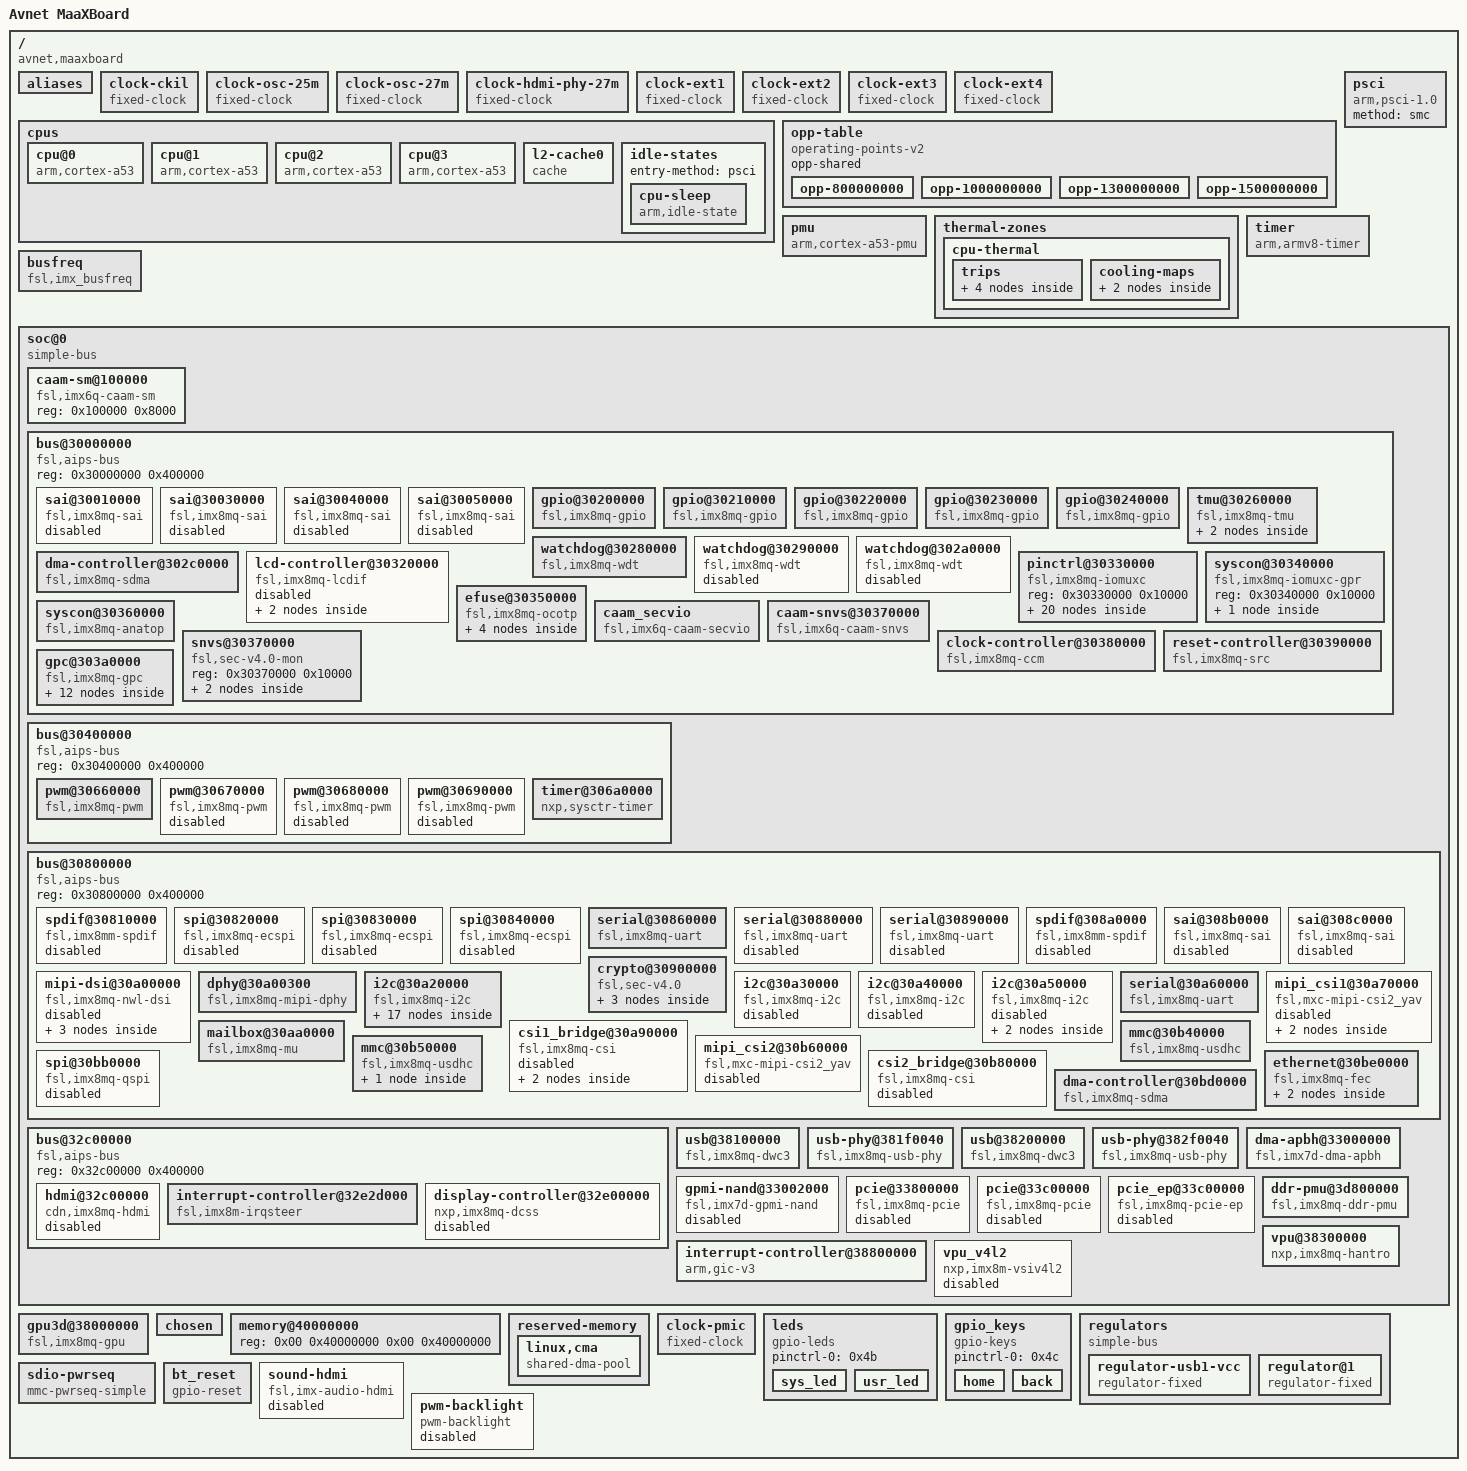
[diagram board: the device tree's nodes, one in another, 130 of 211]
/dts-v1/;

/ {
	interrupt-parent = <0x01>;
	#address-cells = <0x02>;
	#size-cells = <0x02>;
	model = "Avnet MaaXBoard";
	compatible = "avnet,maaxboard", "fsl,imx8mq";

	aliases {
		csi0 = "/soc@0/bus@30800000/mipi_csi1@30a70000";
		csi1 = "/soc@0/bus@30800000/mipi_csi2@30b60000";
		ethernet0 = "/soc@0/bus@30800000/ethernet@30be0000";
		gpio0 = "/soc@0/bus@30000000/gpio@30200000";
		gpio1 = "/soc@0/bus@30000000/gpio@30210000";
		gpio2 = "/soc@0/bus@30000000/gpio@30220000";
		gpio3 = "/soc@0/bus@30000000/gpio@30230000";
		gpio4 = "/soc@0/bus@30000000/gpio@30240000";
		i2c0 = "/soc@0/bus@30800000/i2c@30a20000";
		i2c1 = "/soc@0/bus@30800000/i2c@30a30000";
		i2c2 = "/soc@0/bus@30800000/i2c@30a40000";
		i2c3 = "/soc@0/bus@30800000/i2c@30a50000";
		mmc0 = "/soc@0/bus@30800000/mmc@30b40000";
		mmc1 = "/soc@0/bus@30800000/mmc@30b50000";
		serial0 = "/soc@0/bus@30800000/serial@30860000";
		serial1 = "/soc@0/bus@30800000/serial@30890000";
		serial2 = "/soc@0/bus@30800000/serial@30880000";
		serial3 = "/soc@0/bus@30800000/serial@30a60000";
		spi0 = "/soc@0/bus@30800000/spi@30820000";
		spi1 = "/soc@0/bus@30800000/spi@30830000";
		spi2 = "/soc@0/bus@30800000/spi@30840000";
	};

	clock-ckil {
		compatible = "fixed-clock";
		#clock-cells = <0x00>;
		clock-frequency = <0x8000>;
		clock-output-names = "ckil";
		phandle = <0x17>;
	};

	clock-osc-25m {
		compatible = "fixed-clock";
		#clock-cells = <0x00>;
		clock-frequency = <0x17d7840>;
		clock-output-names = "osc_25m";
		phandle = <0x18>;
	};

	clock-osc-27m {
		compatible = "fixed-clock";
		#clock-cells = <0x00>;
		clock-frequency = <0x19bfcc0>;
		clock-output-names = "osc_27m";
		phandle = <0x19>;
	};

	clock-hdmi-phy-27m {
		compatible = "fixed-clock";
		#clock-cells = <0x00>;
		clock-frequency = <0x19bfcc0>;
		clock-output-names = "hdmi_phy_27m";
		phandle = <0x42>;
	};

	clock-ext1 {
		compatible = "fixed-clock";
		#clock-cells = <0x00>;
		clock-frequency = <0x7ed6b40>;
		clock-output-names = "clk_ext1";
		phandle = <0x1a>;
	};

	clock-ext2 {
		compatible = "fixed-clock";
		#clock-cells = <0x00>;
		clock-frequency = <0x7ed6b40>;
		clock-output-names = "clk_ext2";
		phandle = <0x1b>;
	};

	clock-ext3 {
		compatible = "fixed-clock";
		#clock-cells = <0x00>;
		clock-frequency = <0x7ed6b40>;
		clock-output-names = "clk_ext3";
		phandle = <0x1c>;
	};

	clock-ext4 {
		compatible = "fixed-clock";
		#clock-cells = <0x00>;
		clock-frequency = <0x7ed6b40>;
		clock-output-names = "clk_ext4";
		phandle = <0x1d>;
	};

	cpus {
		#address-cells = <0x01>;
		#size-cells = <0x00>;

		cpu@0 {
			device_type = "cpu";
			compatible = "arm,cortex-a53";
			reg = <0x00>;
			clock-latency = <0xee6c>;
			clocks = <0x02 0x102>;
			enable-method = "psci";
			i-cache-size = <0x8000>;
			i-cache-line-size = <0x40>;
			i-cache-sets = <0x100>;
			d-cache-size = <0x8000>;
			d-cache-line-size = <0x40>;
			d-cache-sets = <0x80>;
			next-level-cache = <0x03>;
			operating-points-v2 = <0x04>;
			#cooling-cells = <0x02>;
			nvmem-cells = <0x05>;
			nvmem-cell-names = "speed_grade";
			cpu-idle-states = <0x06>;
			cpu-supply = <0x07>;
			phandle = <0x0c>;
		};

		cpu@1 {
			device_type = "cpu";
			compatible = "arm,cortex-a53";
			reg = <0x01>;
			clock-latency = <0xee6c>;
			clocks = <0x02 0x102>;
			enable-method = "psci";
			i-cache-size = <0x8000>;
			i-cache-line-size = <0x40>;
			i-cache-sets = <0x100>;
			d-cache-size = <0x8000>;
			d-cache-line-size = <0x40>;
			d-cache-sets = <0x80>;
			next-level-cache = <0x03>;
			operating-points-v2 = <0x04>;
			#cooling-cells = <0x02>;
			cpu-idle-states = <0x06>;
			cpu-supply = <0x07>;
			phandle = <0x0d>;
		};

		cpu@2 {
			device_type = "cpu";
			compatible = "arm,cortex-a53";
			reg = <0x02>;
			clock-latency = <0xee6c>;
			clocks = <0x02 0x102>;
			enable-method = "psci";
			i-cache-size = <0x8000>;
			i-cache-line-size = <0x40>;
			i-cache-sets = <0x100>;
			d-cache-size = <0x8000>;
			d-cache-line-size = <0x40>;
			d-cache-sets = <0x80>;
			next-level-cache = <0x03>;
			operating-points-v2 = <0x04>;
			#cooling-cells = <0x02>;
			cpu-idle-states = <0x06>;
			cpu-supply = <0x07>;
			phandle = <0x0e>;
		};

		cpu@3 {
			device_type = "cpu";
			compatible = "arm,cortex-a53";
			reg = <0x03>;
			clock-latency = <0xee6c>;
			clocks = <0x02 0x102>;
			enable-method = "psci";
			i-cache-size = <0x8000>;
			i-cache-line-size = <0x40>;
			i-cache-sets = <0x100>;
			d-cache-size = <0x8000>;
			d-cache-line-size = <0x40>;
			d-cache-sets = <0x80>;
			next-level-cache = <0x03>;
			operating-points-v2 = <0x04>;
			#cooling-cells = <0x02>;
			cpu-idle-states = <0x06>;
			cpu-supply = <0x07>;
			phandle = <0x0f>;
		};

		l2-cache0 {
			compatible = "cache";
			cache-level = <0x02>;
			cache-size = <0x100000>;
			cache-line-size = <0x40>;
			cache-sets = <0x400>;
			phandle = <0x03>;
		};

		idle-states {
			entry-method = "psci";

			cpu-sleep {
				compatible = "arm,idle-state";
				arm,psci-suspend-param = <0x10033>;
				local-timer-stop;
				entry-latency-us = <0x3e8>;
				exit-latency-us = <0x2bc>;
				min-residency-us = <0xa8c>;
				wakeup-latency-us = <0x5dc>;
				phandle = <0x06>;
			};
		};
	};

	opp-table {
		compatible = "operating-points-v2";
		opp-shared;
		phandle = <0x04>;

		opp-800000000 {
			opp-hz = <0x00 0x2faf0800>;
			opp-microvolt = <0xdbba0>;
			opp-supported-hw = <0x0f 0x04>;
			clock-latency-ns = <0x249f0>;
			opp-suspend;
		};

		opp-1000000000 {
			opp-hz = <0x00 0x3b9aca00>;
			opp-microvolt = <0xdbba0>;
			opp-supported-hw = <0x0e 0x03>;
			clock-latency-ns = <0x249f0>;
			opp-suspend;
		};

		opp-1300000000 {
			opp-hz = <0x00 0x4d7c6d00>;
			opp-microvolt = <0xf4240>;
			opp-supported-hw = <0x0c 0x04>;
			clock-latency-ns = <0x249f0>;
			opp-suspend;
		};

		opp-1500000000 {
			opp-hz = <0x00 0x59682f00>;
			opp-microvolt = <0xf4240>;
			opp-supported-hw = <0x08 0x03>;
			clock-latency-ns = <0x249f0>;
			opp-suspend;
		};
	};

	pmu {
		compatible = "arm,cortex-a53-pmu";
		interrupts = <0x01 0x07 0x04>;
		interrupt-parent = <0x08>;
	};

	psci {
		compatible = "arm,psci-1.0";
		method = "smc";
	};

	thermal-zones {

		cpu-thermal {
			polling-delay-passive = <0xfa>;
			polling-delay = <0x7d0>;
			thermal-sensors = <0x09 0x00>;
			phandle = <0x53>;

			trips {

				cpu-alert {
					temperature = <0x13880>;
					hysteresis = <0x7d0>;
					type = "passive";
					phandle = <0x54>;
				};

				cpu-crit {
					temperature = <0x17318>;
					hysteresis = <0x7d0>;
					type = "critical";
				};

				trip0 {
					temperature = <0x13880>;
					hysteresis = <0x7d0>;
					type = "passive";
					phandle = <0x0a>;
				};

				trip1 {
					temperature = <0x14c08>;
					hysteresis = <0x7d0>;
					type = "passive";
					phandle = <0x10>;
				};
			};

			cooling-maps {

				map0 {
					trip = <0x0a>;
					cooling-device = <0x0b 0x00 0x01 0x0c 0xffffffff 0xffffffff 0x0d 0xffffffff 0xffffffff 0x0e 0xffffffff 0xffffffff 0x0f 0xffffffff 0xffffffff>;
				};

				map1 {
					trip = <0x10>;
					cooling-device = <0x0b 0x00 0x02>;
				};
			};
		};
	};

	timer {
		compatible = "arm,armv8-timer";
		interrupts = <0x01 0x0d 0x08 0x01 0x0e 0x08 0x01 0x0b 0x08 0x01 0x0a 0x08>;
		interrupt-parent = <0x08>;
		arm,no-tick-in-suspend;
	};

	busfreq {
		compatible = "fsl,imx_busfreq";
		clocks = <0x02 0xea 0x02 0x76 0x02 0x77 0x02 0x77 0x02 0xfc 0x02 0xfb 0x02 0x46 0x02 0x4d 0x02 0x48 0x02 0x4e 0x02 0x71 0x02 0x67 0x02 0x74 0x02 0x02 0x02 0x55 0x02 0x49>;
		clock-names = "dram_pll", "dram_alt_src", "dram_apb_src", "dram_apb_pre_div", "dram_core", "dram_alt_root", "sys1_pll_40m", "sys1_pll_400m", "sys1_pll_100m", "sys1_pll_800m", "noc_div", "main_axi_src", "ahb_div", "osc_25m", "sys2_pll_333m", "sys1_pll_133m";
		interrupts = <0x00 0x66 0x04 0x00 0x6d 0x04 0x00 0x6e 0x04 0x00 0x6f 0x04>;
		interrupt-name = "irq_busfreq_0", "irq_busfreq_1", "irq_busfreq_2", "irq_busfreq_3";
	};

	soc@0 {
		compatible = "simple-bus";
		#address-cells = <0x01>;
		#size-cells = <0x01>;
		ranges = <0x00 0x00 0x00 0x3e000000>;
		dma-ranges = <0x40000000 0x00 0x40000000 0xc0000000>;
		nvmem-cells = <0x11>;
		nvmem-cell-names = "soc_unique_id";
		phandle = <0x55>;

		caam-sm@100000 {
			compatible = "fsl,imx6q-caam-sm";
			reg = <0x100000 0x8000>;
			phandle = <0x56>;
		};

		bus@30000000 {
			compatible = "fsl,aips-bus", "simple-bus";
			reg = <0x30000000 0x400000>;
			#address-cells = <0x01>;
			#size-cells = <0x01>;
			ranges = <0x30000000 0x30000000 0x400000>;
			phandle = <0x57>;

			sai@30010000 {
				#sound-dai-cells = <0x00>;
				compatible = "fsl,imx8mq-sai", "fsl,imx6sx-sai";
				reg = <0x30010000 0x10000>;
				interrupts = <0x00 0x5f 0x04>;
				clocks = <0x02 0xee 0x02 0x00 0x02 0xc4 0x02 0x00 0x02 0x00>;
				clock-names = "bus", "mclk0", "mclk1", "mclk2", "mclk3";
				dmas = <0x12 0x08 0x01 0x00 0x12 0x09 0x01 0x00>;
				dma-names = "rx", "tx";
				fsl,dataline = <0x00 0xff 0xff>;
				status = "disabled";
				phandle = <0x58>;
			};

			sai@30030000 {
				#sound-dai-cells = <0x00>;
				compatible = "fsl,imx8mq-sai", "fsl,imx6sx-sai";
				reg = <0x30030000 0x10000>;
				interrupts = <0x00 0x5a 0x04>;
				clocks = <0x02 0xf3 0x02 0x00 0x02 0xc9 0x02 0x00 0x02 0x00>;
				clock-names = "bus", "mclk0", "mclk1", "mclk2", "mclk3";
				dmas = <0x12 0x04 0x18 0x00 0x12 0x05 0x18 0x00>;
				dma-names = "rx", "tx";
				fsl,shared-interrupt;
				status = "disabled";
				phandle = <0x59>;
			};

			sai@30040000 {
				#sound-dai-cells = <0x00>;
				compatible = "fsl,imx8mq-sai", "fsl,imx6sx-sai";
				reg = <0x30040000 0x10000>;
				interrupts = <0x00 0x5a 0x04>;
				clocks = <0x02 0xf2 0x02 0x00 0x02 0xc8 0x02 0x00 0x02 0x00>;
				clock-names = "bus", "mclk0", "mclk1", "mclk2", "mclk3";
				dmas = <0x12 0x02 0x18 0x00 0x12 0x03 0x18 0x00>;
				dma-names = "rx", "tx";
				fsl,shared-interrupt;
				fsl,dataline = <0x00 0x0f 0x0f>;
				status = "disabled";
				phandle = <0x5a>;
			};

			sai@30050000 {
				#sound-dai-cells = <0x00>;
				compatible = "fsl,imx8mq-sai", "fsl,imx6sx-sai";
				reg = <0x30050000 0x10000>;
				interrupts = <0x00 0x64 0x04>;
				clocks = <0x02 0xf1 0x02 0x00 0x02 0xc7 0x02 0x00 0x02 0x00 0x02 0x1b 0x02 0x20>;
				clock-names = "bus", "mclk0", "mclk1", "mclk2", "mclk3", "pll8k", "pll11k";
				dmas = <0x12 0x00 0x18 0x00 0x12 0x01 0x18 0x00>;
				dma-names = "rx", "tx";
				fsl,dataline = <0x00 0x00 0x0f>;
				status = "disabled";
				assigned-clocks = <0x02 0x84>;
				assigned-clock-parents = <0x02 0x1b>;
				assigned-clock-rates = <0x1770000>;
				phandle = <0x51>;
			};

			gpio@30200000 {
				compatible = "fsl,imx8mq-gpio", "fsl,imx35-gpio";
				reg = <0x30200000 0x10000>;
				interrupts = <0x00 0x40 0x04 0x00 0x41 0x04>;
				clocks = <0x02 0x103>;
				gpio-controller;
				#gpio-cells = <0x02>;
				interrupt-controller;
				#interrupt-cells = <0x02>;
				gpio-ranges = <0x13 0x00 0x0a 0x1e>;
				phandle = <0x2c>;
			};

			gpio@30210000 {
				compatible = "fsl,imx8mq-gpio", "fsl,imx35-gpio";
				reg = <0x30210000 0x10000>;
				interrupts = <0x00 0x42 0x04 0x00 0x43 0x04>;
				clocks = <0x02 0x104>;
				gpio-controller;
				#gpio-cells = <0x02>;
				interrupt-controller;
				#interrupt-cells = <0x02>;
				gpio-ranges = <0x13 0x00 0x28 0x15>;
				phandle = <0x3c>;
			};

			gpio@30220000 {
				compatible = "fsl,imx8mq-gpio", "fsl,imx35-gpio";
				reg = <0x30220000 0x10000>;
				interrupts = <0x00 0x44 0x04 0x00 0x45 0x04>;
				clocks = <0x02 0x105>;
				gpio-controller;
				#gpio-cells = <0x02>;
				interrupt-controller;
				#interrupt-cells = <0x02>;
				gpio-ranges = <0x13 0x00 0x3d 0x1a>;
				phandle = <0x2f>;
			};

			gpio@30230000 {
				compatible = "fsl,imx8mq-gpio", "fsl,imx35-gpio";
				reg = <0x30230000 0x10000>;
				interrupts = <0x00 0x46 0x04 0x00 0x47 0x04>;
				clocks = <0x02 0x106>;
				gpio-controller;
				#gpio-cells = <0x02>;
				interrupt-controller;
				#interrupt-cells = <0x02>;
				gpio-ranges = <0x13 0x00 0x57 0x20>;
				phandle = <0x5b>;
			};

			gpio@30240000 {
				compatible = "fsl,imx8mq-gpio", "fsl,imx35-gpio";
				reg = <0x30240000 0x10000>;
				interrupts = <0x00 0x48 0x04 0x00 0x49 0x04>;
				clocks = <0x02 0x107>;
				gpio-controller;
				#gpio-cells = <0x02>;
				interrupt-controller;
				#interrupt-cells = <0x02>;
				gpio-ranges = <0x13 0x00 0x77 0x1e>;
				phandle = <0x50>;
			};

			tmu@30260000 {
				compatible = "fsl,imx8mq-tmu";
				reg = <0x30260000 0x10000>;
				interrupts = <0x00 0x31 0x04>;
				clocks = <0x02 0xf6>;
				little-endian;
				fsl,tmu-range = <0xb0000 0xa0026 0x80048 0x70061>;
				fsl,tmu-calibration = <0x00 0x23 0x01 0x29 0x02 0x2f 0x03 0x35 0x04 0x3d 0x05 0x43 0x06 0x4b 0x07 0x51 0x08 0x57 0x09 0x5f 0x0a 0x67 0x0b 0x6f 0x10000 0x1b 0x10001 0x23 0x10002 0x2b 0x10003 0x33 0x10004 0x3b 0x10005 0x43 0x10006 0x4b 0x10007 0x55 0x10008 0x5d 0x10009 0x67 0x1000a 0x70 0x20000 0x17 0x20001 0x23 0x20002 0x2d 0x20003 0x37 0x20004 0x41 0x20005 0x4b 0x20006 0x57 0x20007 0x63 0x20008 0x6f 0x30000 0x15 0x30001 0x21 0x30002 0x2d 0x30003 0x39 0x30004 0x45 0x30005 0x53 0x30006 0x5f 0x30007 0x71>;
				#thermal-sensor-cells = <0x01>;
				phandle = <0x09>;

				throttle-cfgs {

					devfreq {
						throttle,max_state = <0x02>;
						#cooling-cells = <0x02>;
						phandle = <0x0b>;
					};
				};
			};

			watchdog@30280000 {
				compatible = "fsl,imx8mq-wdt", "fsl,imx21-wdt";
				reg = <0x30280000 0x10000>;
				interrupts = <0x00 0x4e 0x04>;
				clocks = <0x02 0xd4>;
				status = "okay";
				pinctrl-names = "default";
				pinctrl-0 = <0x14>;
				fsl,ext-reset-output;
				phandle = <0x5c>;
			};

			watchdog@30290000 {
				compatible = "fsl,imx8mq-wdt", "fsl,imx21-wdt";
				reg = <0x30290000 0x10000>;
				interrupts = <0x00 0x4f 0x04>;
				clocks = <0x02 0xd5>;
				status = "disabled";
				phandle = <0x5d>;
			};

			watchdog@302a0000 {
				compatible = "fsl,imx8mq-wdt", "fsl,imx21-wdt";
				reg = <0x302a0000 0x10000>;
				interrupts = <0x00 0x0a 0x04>;
				clocks = <0x02 0xd6>;
				status = "disabled";
				phandle = <0x5e>;
			};

			dma-controller@302c0000 {
				compatible = "fsl,imx8mq-sdma", "fsl,imx7d-sdma";
				reg = <0x302c0000 0x10000>;
				interrupts = <0x00 0x67 0x04>;
				clocks = <0x02 0xe4 0x02 0xe4>;
				clock-names = "ipg", "ahb";
				#dma-cells = <0x03>;
				fsl,sdma-ram-script-name = "imx/sdma/sdma-imx7d.bin";
				phandle = <0x12>;
			};

			lcd-controller@30320000 {
				compatible = "fsl,imx8mq-lcdif", "fsl,imx28-lcdif";
				reg = <0x30320000 0x10000>;
				interrupts = <0x00 0x05 0x04>;
				clocks = <0x02 0x80>;
				clock-names = "pix";
				assigned-clocks = <0x02 0x21 0x02 0x24 0x02 0x80 0x02 0x23>;
				assigned-clock-parents = <0x02 0x02 0x02 0x23 0x02 0x25>;
				assigned-clock-rates = <0x00 0x00 0x00 0x2367b880>;
				status = "disabled";
				phandle = <0x5f>;

				port {

					endpoint {
						remote-endpoint = <0x15>;
						phandle = <0x28>;
					};
				};
			};

			pinctrl@30330000 {
				compatible = "fsl,imx8mq-iomuxc";
				reg = <0x30330000 0x10000>;
				pinctrl-names = "default";
				phandle = <0x13>;

				ir-recv {
					fsl,pins = <0x58 0x2c0 0x00 0x00 0x00 0x4f>;
					phandle = <0x60>;
				};

				pmicirq {
					fsl,pins = <0x44 0x2ac 0x00 0x00 0x00 0x19>;
					phandle = <0x2a>;
				};

				fec1grp {
					fsl,pins = <0x68 0x2d0 0x00 0x00 0x00 0x03 0x6c 0x2d4 0x4c0 0x00 0x01 0x23 0x70 0x2d8 0x00 0x00 0x00 0x1f 0x74 0x2dc 0x00 0x00 0x00 0x1f 0x78 0x2e0 0x00 0x00 0x00 0x1f 0x7c 0x2e4 0x00 0x00 0x00 0x1f 0x9c 0x304 0x00 0x00 0x00 0x91 0x98 0x300 0x00 0x00 0x00 0x91 0x94 0x2fc 0x00 0x00 0x00 0x91 0x90 0x2f8 0x00 0x00 0x00 0x91 0x84 0x2ec 0x00 0x00 0x00 0x1f 0x8c 0x2f4 0x00 0x00 0x00 0x91 0x88 0x2f0 0x00 0x00 0x00 0x91 0x80 0x2e8 0x00 0x00 0x00 0x1f 0x4c 0x2b4 0x00 0x00 0x00 0x19>;
					phandle = <0x3f>;
				};

				i2c1grp {
					fsl,pins = <0x214 0x47c 0x00 0x00 0x00 0x4000007f 0x218 0x480 0x00 0x00 0x00 0x4000007f>;
					phandle = <0x29>;
				};

				uart1grp {
					fsl,pins = <0x234 0x49c 0x4f4 0x00 0x00 0x49 0x238 0x4a0 0x00 0x00 0x00 0x49>;
					phandle = <0x23>;
				};

				usdhc1grp {
					fsl,pins = <0xa0 0x308 0x00 0x00 0x00 0x83 0xa4 0x30c 0x00 0x00 0x00 0xc3 0xa8 0x310 0x00 0x00 0x00 0xc3 0xac 0x314 0x00 0x00 0x00 0xc3 0xb0 0x318 0x00 0x00 0x00 0xc3 0xb4 0x31c 0x00 0x00 0x00 0xc3 0xb8 0x320 0x00 0x00 0x00 0xc3 0xbc 0x324 0x00 0x00 0x00 0xc3 0xc0 0x328 0x00 0x00 0x00 0xc3 0xc4 0x32c 0x00 0x00 0x00 0xc3 0xcc 0x334 0x00 0x00 0x00 0x83 0xc8 0x330 0x00 0x00 0x00 0xc1>;
					phandle = <0x36>;
				};

				usdhc1-100grp {
					fsl,pins = <0xa0 0x308 0x00 0x00 0x00 0x8d 0xa4 0x30c 0x00 0x00 0x00 0xcd 0xa8 0x310 0x00 0x00 0x00 0xcd 0xac 0x314 0x00 0x00 0x00 0xcd 0xb0 0x318 0x00 0x00 0x00 0xcd 0xb4 0x31c 0x00 0x00 0x00 0xcd 0xb8 0x320 0x00 0x00 0x00 0xcd 0xbc 0x324 0x00 0x00 0x00 0xcd 0xc0 0x328 0x00 0x00 0x00 0xcd 0xc4 0x32c 0x00 0x00 0x00 0xcd 0xcc 0x334 0x00 0x00 0x00 0x8d 0xc8 0x330 0x00 0x00 0x00 0xc1>;
					phandle = <0x37>;
				};

				usdhc1-200grp {
					fsl,pins = <0xa0 0x308 0x00 0x00 0x00 0x9f 0xa4 0x30c 0x00 0x00 0x00 0xdf 0xa8 0x310 0x00 0x00 0x00 0xdf 0xac 0x314 0x00 0x00 0x00 0xdf 0xb0 0x318 0x00 0x00 0x00 0xdf 0xb4 0x31c 0x00 0x00 0x00 0xdf 0xb8 0x320 0x00 0x00 0x00 0xdf 0xbc 0x324 0x00 0x00 0x00 0xdf 0xc0 0x328 0x00 0x00 0x00 0xdf 0xc4 0x32c 0x00 0x00 0x00 0xdf 0xcc 0x334 0x00 0x00 0x00 0x9f 0xc8 0x330 0x00 0x00 0x00 0xc1>;
					phandle = <0x38>;
				};

				gpio_ledsgrp {
					fsl,pins = <0x3c 0x2a4 0x00 0x00 0x00 0x19 0x48 0x2b0 0x00 0x00 0x00 0x19>;
					phandle = <0x4b>;
				};

				gpio_keysgrp {
					fsl,pins = <0x110 0x378 0x00 0x05 0x00 0x56 0x10c 0x374 0x00 0x05 0x00 0x56>;
					phandle = <0x4c>;
				};

				usb1_pwr_en {
					fsl,pins = <0x58 0x2c0 0x00 0x00 0x00 0x16>;
					phandle = <0x4d>;
				};

				usdhc2grp {
					fsl,pins = <0xd4 0x33c 0x00 0x00 0x00 0x83 0xd8 0x340 0x00 0x00 0x00 0xc3 0xdc 0x344 0x00 0x00 0x00 0xc3 0xe0 0x348 0x00 0x00 0x00 0xc3 0xe4 0x34c 0x00 0x00 0x00 0xc3 0xe8 0x350 0x00 0x00 0x00 0xc3>;
					phandle = <0x39>;
				};

				wlangrp {
					fsl,pins = <0xec 0x354 0x00 0x05 0x00 0x19 0xd0 0x338 0x00 0x05 0x00 0x19 0x28 0x290 0x00 0x05 0x00 0x05>;
					phandle = <0x4f>;
				};

				reg3V3wfgrp {
					fsl,pins = <0xf0 0x358 0x00 0x05 0x00 0x19>;
					phandle = <0x4e>;
				};

				uart4grp {
					fsl,pins = <0x24c 0x4b4 0x50c 0x00 0x02 0x49 0x250 0x4b8 0x00 0x00 0x00 0x49 0x210 0x478 0x508 0x01 0x01 0x49 0x20c 0x474 0x00 0x01 0x00 0x49 0x208 0x470 0x00 0x05 0x00 0x19>;
					phandle = <0x30>;
				};

				pwm1_grp {
					fsl,pins = <0x2c 0x294 0x00 0x01 0x00 0x06>;
					phandle = <0x21>;
				};

				ts_pinsgrp {
					fsl,pins = <0x128 0x390 0x00 0x05 0x00 0x19 0x38 0x2a0 0x00 0x00 0x00 0x19>;
					phandle = <0x2e>;
				};

				i2c4grp {
					fsl,pins = <0x22c 0x494 0x00 0x00 0x00 0x4000007f 0x230 0x498 0x00 0x00 0x00 0x4000007f>;
					phandle = <0x2d>;
				};

				csi1grp {
					fsl,pins = <0x13c 0x3a4 0x00 0x05 0x00 0x19 0x12c 0x394 0x00 0x05 0x00 0x19>;
					phandle = <0x61>;
				};

				wdog1grp {
					fsl,pins = <0x30 0x298 0x00 0x01 0x00 0xc6>;
					phandle = <0x14>;
				};
			};

			syscon@30340000 {
				compatible = "fsl,imx8mq-iomuxc-gpr", "fsl,imx6q-iomuxc-gpr", "syscon", "simple-mfd";
				reg = <0x30340000 0x10000>;
				phandle = <0x33>;

				mux-controller {
					compatible = "mmio-mux";
					#mux-control-cells = <0x01>;
					mux-reg-masks = <0x34 0x04>;
					phandle = <0x24>;
				};
			};

			efuse@30350000 {
				compatible = "fsl,imx8mq-ocotp", "syscon", "simple-mfd";
				reg = <0x30350000 0x10000>;
				clocks = <0x02 0xfa>;
				#address-cells = <0x01>;
				#size-cells = <0x01>;
				phandle = <0x62>;

				soc-uid@4 {
					reg = <0x04 0x08>;
					phandle = <0x11>;
				};

				speed-grade@10 {
					reg = <0x10 0x04>;
					phandle = <0x05>;
				};

				mac-address@90 {
					reg = <0x90 0x06>;
					phandle = <0x3e>;
				};

				imx8mq-soc {
					compatible = "fsl,imx8mq-soc";
					nvmem-cells = <0x11>;
					nvmem-cell-names = "soc_unique_id";
					phandle = <0x63>;
				};
			};

			syscon@30360000 {
				compatible = "fsl,imx8mq-anatop", "syscon";
				reg = <0x30360000 0x10000>;
				interrupts = <0x00 0x31 0x04>;
				phandle = <0x64>;
			};

			caam_secvio {
				compatible = "fsl,imx6q-caam-secvio";
				interrupts = <0x00 0x14 0x04>;
				jtag-tamper = "disabled";
				watchdog-tamper = "enabled";
				internal-boot-tamper = "enabled";
				external-pin-tamper = "disabled";
				phandle = <0x65>;
			};

			caam-snvs@30370000 {
				compatible = "fsl,imx6q-caam-snvs";
				reg = <0x30370000 0x10000>;
				clocks = <0x02 0x108>;
				clock-names = "ipg";
				phandle = <0x66>;
			};

			snvs@30370000 {
				compatible = "fsl,sec-v4.0-mon", "syscon", "simple-mfd";
				reg = <0x30370000 0x10000>;
				phandle = <0x16>;

				snvs-rtc-lp {
					compatible = "fsl,sec-v4.0-mon-rtc-lp";
					regmap = <0x16>;
					offset = <0x34>;
					interrupts = <0x00 0x13 0x04 0x00 0x14 0x04>;
					clocks = <0x02 0x108>;
					clock-names = "snvs-rtc";
					phandle = <0x67>;
				};

				snvs-powerkey {
					compatible = "fsl,sec-v4.0-pwrkey";
					regmap = <0x16>;
					interrupts = <0x00 0x04 0x04>;
					clocks = <0x02 0x108>;
					clock-names = "snvs-pwrkey";
					linux,keycode = <0x74>;
					wakeup-source;
					status = "okay";
					phandle = <0x68>;
				};
			};

			clock-controller@30380000 {
				compatible = "fsl,imx8mq-ccm";
				reg = <0x30380000 0x10000>;
				interrupts = <0x00 0x55 0x04 0x00 0x56 0x04>;
				#clock-cells = <0x01>;
				clocks = <0x17 0x18 0x19 0x1a 0x1b 0x1c 0x1d>;
				clock-names = "ckil", "osc_25m", "osc_27m", "clk_ext1", "clk_ext2", "clk_ext3", "clk_ext4";
				assigned-clocks = <0x02 0x58 0x02 0x121 0x02 0x71 0x02 0x75 0x02 0x1a 0x02 0x1f 0x02 0x19 0x02 0x1e 0x02 0x69>;
				assigned-clock-rates = <0x00 0x00 0x2faf0800 0x00 0x00 0x00 0x2ee00000 0x2b110000 0x00>;
				assigned-clock-parents = <0x02 0x4e 0x02 0x0c 0x02 0x4e 0x02 0x56 0x02 0x19 0x02 0x1e 0x00 0x00 0x02 0x4c>;
				phandle = <0x02>;
			};

			reset-controller@30390000 {
				compatible = "fsl,imx8mq-src", "syscon";
				reg = <0x30390000 0x10000>;
				interrupts = <0x00 0x59 0x04>;
				#reset-cells = <0x01>;
				phandle = <0x27>;
			};

			gpc@303a0000 {
				compatible = "fsl,imx8mq-gpc";
				reg = <0x303a0000 0x10000>;
				interrupts = <0x00 0x57 0x04>;
				interrupt-parent = <0x08>;
				interrupt-controller;
				broken-wake-request-signals;
				#interrupt-cells = <0x03>;
				phandle = <0x01>;

				pgc {
					#address-cells = <0x01>;
					#size-cells = <0x00>;

					power-domain@0 {
						#power-domain-cells = <0x00>;
						reg = <0x00>;
						phandle = <0x25>;
					};

					power-domain@1 {
						#power-domain-cells = <0x00>;
						reg = <0x01>;
						power-domains = <0x1e>;
						phandle = <0x48>;
					};

					power-domain@2 {
						#power-domain-cells = <0x00>;
						reg = <0x02>;
						phandle = <0x44>;
					};

					power-domain@3 {
						#power-domain-cells = <0x00>;
						reg = <0x03>;
						phandle = <0x46>;
					};

					power-domain@4 {
						#power-domain-cells = <0x00>;
						reg = <0x04>;
						phandle = <0x69>;
					};

					power-domain@5 {
						#power-domain-cells = <0x00>;
						reg = <0x05>;
						clocks = <0x02 0xd7 0x02 0x66 0x02 0x6f 0x02 0x70>;
						power-supply = <0x1f>;
						phandle = <0x4a>;
					};

					power-domain@6 {
						#power-domain-cells = <0x00>;
						reg = <0x06>;
						clocks = <0x02 0xdf 0x02 0xe5 0x02 0xe6>;
						assigned-clocks = <0x02 0x78 0x02 0x79 0x02 0x6a 0x02 0x15>;
						assigned-clock-parents = <0x02 0x16 0x02 0x16 0x02 0x4e 0x02 0x14>;
						assigned-clock-rates = <0x23c34600 0x23c34600 0x2faf0800 0x00>;
						power-supply = <0x20>;
						phandle = <0x49>;
					};

					power-domain@7 {
						#power-domain-cells = <0x00>;
						reg = <0x07>;
						phandle = <0x6a>;
					};

					power-domain@8 {
						#power-domain-cells = <0x00>;
						reg = <0x08>;
						phandle = <0x32>;
					};

					power-domain@9 {
						#power-domain-cells = <0x00>;
						reg = <0x09>;
						phandle = <0x3d>;
					};

					power-domain@a {
						#power-domain-cells = <0x00>;
						reg = <0x0a>;
						phandle = <0x1e>;
					};
				};
			};
		};

		bus@30400000 {
			compatible = "fsl,aips-bus", "simple-bus";
			reg = <0x30400000 0x400000>;
			#address-cells = <0x01>;
			#size-cells = <0x01>;
			ranges = <0x30400000 0x30400000 0x400000>;
			phandle = <0x6b>;

			pwm@30660000 {
				compatible = "fsl,imx8mq-pwm", "fsl,imx27-pwm";
				reg = <0x30660000 0x10000>;
				interrupts = <0x00 0x51 0x04>;
				clocks = <0x02 0xbf 0x02 0xbf>;
				clock-names = "ipg", "per";
				#pwm-cells = <0x03>;
				status = "okay";
				pinctrl-names = "default";
				pinctrl-0 = <0x21>;
				phandle = <0x52>;
			};

			pwm@30670000 {
				compatible = "fsl,imx8mq-pwm", "fsl,imx27-pwm";
				reg = <0x30670000 0x10000>;
				interrupts = <0x00 0x52 0x04>;
				clocks = <0x02 0xc0 0x02 0xc0>;
				clock-names = "ipg", "per";
				#pwm-cells = <0x03>;
				status = "disabled";
				phandle = <0x6c>;
			};

			pwm@30680000 {
				compatible = "fsl,imx8mq-pwm", "fsl,imx27-pwm";
				reg = <0x30680000 0x10000>;
				interrupts = <0x00 0x53 0x04>;
				clocks = <0x02 0xc1 0x02 0xc1>;
				clock-names = "ipg", "per";
				#pwm-cells = <0x03>;
				status = "disabled";
				phandle = <0x6d>;
			};

			pwm@30690000 {
				compatible = "fsl,imx8mq-pwm", "fsl,imx27-pwm";
				reg = <0x30690000 0x10000>;
				interrupts = <0x00 0x54 0x04>;
				clocks = <0x02 0xc2 0x02 0xc2>;
				clock-names = "ipg", "per";
				#pwm-cells = <0x03>;
				status = "disabled";
				phandle = <0x6e>;
			};

			timer@306a0000 {
				compatible = "nxp,sysctr-timer";
				reg = <0x306a0000 0x20000>;
				interrupts = <0x00 0x2f 0x04>;
				clocks = <0x18>;
				clock-names = "per";
				phandle = <0x6f>;
			};
		};

		bus@30800000 {
			compatible = "fsl,aips-bus", "simple-bus";
			reg = <0x30800000 0x400000>;
			#address-cells = <0x01>;
			#size-cells = <0x01>;
			ranges = <0x30800000 0x30800000 0x400000 0x8000000 0x8000000 0x10000000>;
			phandle = <0x70>;

			spdif@30810000 {
				compatible = "fsl,imx8mm-spdif", "fsl,imx35-spdif";
				reg = <0x30810000 0x10000>;
				interrupts = <0x00 0x06 0x04>;
				clocks = <0x02 0xec 0x02 0x02 0x02 0x87 0x02 0x00 0x02 0x00 0x02 0x00 0x02 0xec 0x02 0x00 0x02 0x00 0x02 0x00>;
				clock-names = "core", "rxtx0", "rxtx1", "rxtx2", "rxtx3", "rxtx4", "rxtx5", "rxtx6", "rxtx7", "spba";
				dmas = <0x22 0x08 0x12 0x00 0x22 0x09 0x12 0x00>;
				dma-names = "rx", "tx";
				status = "disabled";
				phandle = <0x71>;
			};

			spi@30820000 {
				#address-cells = <0x01>;
				#size-cells = <0x00>;
				compatible = "fsl,imx8mq-ecspi", "fsl,imx51-ecspi";
				reg = <0x30820000 0x10000>;
				interrupts = <0x00 0x1f 0x04>;
				clocks = <0x02 0xb3 0x02 0xb3>;
				clock-names = "ipg", "per";
				dmas = <0x22 0x00 0x07 0x01 0x22 0x01 0x07 0x02>;
				dma-names = "rx", "tx";
				status = "disabled";
				phandle = <0x72>;
			};

			spi@30830000 {
				#address-cells = <0x01>;
				#size-cells = <0x00>;
				compatible = "fsl,imx8mq-ecspi", "fsl,imx51-ecspi";
				reg = <0x30830000 0x10000>;
				interrupts = <0x00 0x20 0x04>;
				clocks = <0x02 0xb4 0x02 0xb4>;
				clock-names = "ipg", "per";
				dmas = <0x22 0x02 0x07 0x01 0x22 0x03 0x07 0x02>;
				dma-names = "rx", "tx";
				status = "disabled";
				phandle = <0x73>;
			};

			spi@30840000 {
				#address-cells = <0x01>;
				#size-cells = <0x00>;
				compatible = "fsl,imx8mq-ecspi", "fsl,imx51-ecspi";
				reg = <0x30840000 0x10000>;
				interrupts = <0x00 0x21 0x04>;
				clocks = <0x02 0xb5 0x02 0xb5>;
				clock-names = "ipg", "per";
				dmas = <0x22 0x04 0x07 0x01 0x22 0x05 0x07 0x02>;
				dma-names = "rx", "tx";
				status = "disabled";
				phandle = <0x74>;
			};

			serial@30860000 {
				compatible = "fsl,imx8mq-uart", "fsl,imx6q-uart";
				reg = <0x30860000 0x10000>;
				interrupts = <0x00 0x1a 0x04>;
				clocks = <0x02 0xca 0x02 0xca>;
				clock-names = "ipg", "per";
				status = "okay";
				pinctrl-names = "default";
				pinctrl-0 = <0x23>;
				assigned-clocks = <0x02 0x94>;
				assigned-clock-parents = <0x02 0x02>;
				phandle = <0x75>;
			};

			serial@30880000 {
				compatible = "fsl,imx8mq-uart", "fsl,imx6q-uart";
				reg = <0x30880000 0x10000>;
				interrupts = <0x00 0x1c 0x04>;
				clocks = <0x02 0xcc 0x02 0xcc>;
				clock-names = "ipg", "per";
				dmas = <0x22 0x1a 0x04 0x00 0x22 0x1b 0x04 0x00>;
				dma-names = "rx", "tx";
				status = "disabled";
				phandle = <0x76>;
			};

			serial@30890000 {
				compatible = "fsl,imx8mq-uart", "fsl,imx6q-uart";
				reg = <0x30890000 0x10000>;
				interrupts = <0x00 0x1b 0x04>;
				clocks = <0x02 0xcb 0x02 0xcb>;
				clock-names = "ipg", "per";
				dmas = <0x22 0x18 0x04 0x00 0x22 0x19 0x04 0x00>;
				dma-names = "rx", "tx";
				status = "disabled";
				phandle = <0x77>;
			};

			spdif@308a0000 {
				compatible = "fsl,imx8mm-spdif", "fsl,imx35-spdif";
				reg = <0x308a0000 0x10000>;
				interrupts = <0x00 0x0d 0x04>;
				clocks = <0x02 0xec 0x02 0x02 0x02 0x88 0x02 0x00 0x02 0x00 0x02 0x00 0x02 0xec 0x02 0x00 0x02 0x00 0x02 0x00>;
				clock-names = "core", "rxtx0", "rxtx1", "rxtx2", "rxtx3", "rxtx4", "rxtx5", "rxtx6", "rxtx7", "spba";
				dmas = <0x22 0x10 0x12 0x00 0x22 0x11 0x12 0x00>;
				dma-names = "rx", "tx";
				status = "disabled";
				phandle = <0x78>;
			};

			sai@308b0000 {
				#sound-dai-cells = <0x00>;
				compatible = "fsl,imx8mq-sai";
				reg = <0x308b0000 0x10000>;
				interrupts = <0x00 0x60 0x04>;
				clocks = <0x02 0xef 0x02 0x00 0x02 0xc5 0x02 0x00 0x02 0x00>;
				clock-names = "bus", "mclk0", "mclk1", "mclk2", "mclk3";
				dmas = <0x22 0x0a 0x18 0x00 0x22 0x0b 0x18 0x00>;
				dma-names = "rx", "tx";
				status = "disabled";
				phandle = <0x79>;
			};

			sai@308c0000 {
				#sound-dai-cells = <0x00>;
				compatible = "fsl,imx8mq-sai", "fsl,imx6sx-sai";
				reg = <0x308c0000 0x10000>;
				interrupts = <0x00 0x32 0x04>;
				clocks = <0x02 0xf0 0x02 0x00 0x02 0xc6 0x02 0x00 0x02 0x00>;
				clock-names = "bus", "mclk0", "mclk1", "mclk2", "mclk3";
				dmas = <0x22 0x0c 0x18 0x00 0x22 0x0d 0x18 0x00>;
				dma-names = "rx", "tx";
				status = "disabled";
				phandle = <0x7a>;
			};

			crypto@30900000 {
				compatible = "fsl,sec-v4.0";
				#address-cells = <0x01>;
				#size-cells = <0x01>;
				reg = <0x30900000 0x40000>;
				ranges = <0x00 0x30900000 0x40000>;
				interrupts = <0x00 0x5b 0x04>;
				clocks = <0x02 0x74 0x02 0xec>;
				clock-names = "aclk", "ipg";
				phandle = <0x7b>;

				jr@1000 {
					compatible = "fsl,sec-v4.0-job-ring";
					reg = <0x1000 0x1000>;
					interrupts = <0x00 0x69 0x04>;
					status = "disabled";
					phandle = <0x7c>;
				};

				jr@2000 {
					compatible = "fsl,sec-v4.0-job-ring";
					reg = <0x2000 0x1000>;
					interrupts = <0x00 0x6a 0x04>;
					phandle = <0x7d>;
				};

				jr@3000 {
					compatible = "fsl,sec-v4.0-job-ring";
					reg = <0x3000 0x1000>;
					interrupts = <0x00 0x72 0x04>;
					phandle = <0x7e>;
				};
			};

			mipi-dsi@30a00000 {
				compatible = "fsl,imx8mq-nwl-dsi";
				reg = <0x30a00000 0x300>;
				clocks = <0x02 0xa3 0x02 0xf4 0x02 0xf5 0x02 0xa4 0x02 0x23 0x02 0x80>;
				clock-names = "core", "rx_esc", "tx_esc", "phy_ref", "video_pll", "lcdif";
				assigned-clocks = <0x02 0xa4 0x02 0xa3 0x02 0xf4 0x02 0xf5>;
				assigned-clock-parents = <0x02 0x25 0x02 0x4c 0x02 0x47>;
				assigned-clock-rates = <0x19bfcc0 0xfdad680 0x4c4b400 0x1312d00>;
				interrupts = <0x00 0x22 0x04>;
				mux-controls = <0x24 0x00>;
				power-domains = <0x25>;
				phys = <0x26>;
				phy-names = "dphy";
				resets = <0x27 0x15 0x27 0x17 0x27 0x18 0x27 0x19>;
				reset-names = "byte", "dpi", "esc", "pclk";
				status = "disabled";
				phandle = <0x7f>;

				ports {
					#address-cells = <0x01>;
					#size-cells = <0x00>;

					port@0 {
						reg = <0x00>;
						#address-cells = <0x01>;
						#size-cells = <0x00>;

						endpoint@0 {
							reg = <0x00>;
							remote-endpoint = <0x28>;
							phandle = <0x15>;
						};
					};
				};
			};

			dphy@30a00300 {
				compatible = "fsl,imx8mq-mipi-dphy";
				reg = <0x30a00300 0x100>;
				clocks = <0x02 0xa4>;
				clock-names = "phy_ref";
				assigned-clocks = <0x02 0x21 0x02 0x24 0x02 0xa4 0x02 0x23>;
				assigned-clock-parents = <0x02 0x02 0x02 0x23 0x02 0x25>;
				assigned-clock-rates = <0x00 0x00 0x16e3600 0x2367b880>;
				#phy-cells = <0x00>;
				power-domains = <0x25>;
				status = "okay";
				phandle = <0x26>;
			};

			i2c@30a20000 {
				compatible = "fsl,imx8mq-i2c", "fsl,imx21-i2c";
				reg = <0x30a20000 0x10000>;
				interrupts = <0x00 0x23 0x04>;
				clocks = <0x02 0xb8>;
				#address-cells = <0x01>;
				#size-cells = <0x00>;
				status = "okay";
				clock-frequency = <0x186a0>;
				pinctrl-names = "default";
				pinctrl-0 = <0x29>;
				phandle = <0x80>;

				pmic@4b {
					compatible = "rohm,bd71837";
					reg = <0x4b>;
					pinctrl-names = "default";
					pinctrl-0 = <0x2a>;
					clocks = <0x2b>;
					clock-names = "osc";
					clock-output-names = "pmic_clk";
					interrupt-parent = <0x2c>;
					interrupts = <0x07 0x01>;
					interrupt-names = "irq";
					rohm,reset-snvs-powered;
					phandle = <0x81>;

					regulators {

						BUCK1 {
							regulator-name = "buck1";
							regulator-min-microvolt = <0xaae60>;
							regulator-max-microvolt = <0x13d620>;
							regulator-boot-on;
							regulator-always-on;
							regulator-ramp-delay = <0x4e2>;
							rohm,dvs-run-voltage = <0xdbba0>;
							rohm,dvs-idle-voltage = <0xcf850>;
							rohm,dvs-suspend-voltage = "", "\f5";
							phandle = <0x82>;
						};

						BUCK2 {
							regulator-name = "buck2";
							regulator-min-microvolt = <0xaae60>;
							regulator-max-microvolt = <0x13d620>;
							regulator-boot-on;
							regulator-always-on;
							regulator-ramp-delay = <0x4e2>;
							rohm,dvs-run-voltage = <0xf4240>;
							rohm,dvs-idle-voltage = <0xdbba0>;
							phandle = <0x07>;
						};

						BUCK3 {
							regulator-name = "buck3";
							regulator-min-microvolt = <0xaae60>;
							regulator-max-microvolt = <0x13d620>;
							regulator-boot-on;
							rohm,dvs-run-voltage = <0xf4240>;
							regulator-enable-ramp-delay = <0xb4>;
							phandle = <0x1f>;
						};

						BUCK4 {
							regulator-name = "buck4";
							regulator-min-microvolt = <0xaae60>;
							regulator-max-microvolt = <0x13d620>;
							rohm,dvs-run-voltage = <0xf4240>;
							regulator-boot-on;
							regulator-enable-ramp-delay = <0xb4>;
							phandle = <0x20>;
						};

						BUCK5 {
							regulator-name = "buck5";
							regulator-min-microvolt = <0xdbba0>;
							regulator-max-microvolt = <0xf4240>;
							regulator-boot-on;
							regulator-always-on;
							phandle = <0x83>;
						};

						BUCK6 {
							regulator-name = "buck6";
							regulator-min-microvolt = <0x2dc6c0>;
							regulator-max-microvolt = <0x325aa0>;
							regulator-boot-on;
							regulator-always-on;
							phandle = <0x84>;
						};

						BUCK7 {
							regulator-name = "buck7";
							regulator-min-microvolt = <0x1b7740>;
							regulator-max-microvolt = <0x1cfde0>;
							regulator-boot-on;
							regulator-always-on;
							phandle = <0x85>;
						};

						BUCK8 {
							regulator-name = "buck8";
							regulator-min-microvolt = <0x124f80>;
							regulator-max-microvolt = <0x13d620>;
							regulator-boot-on;
							regulator-always-on;
							phandle = <0x86>;
						};

						LDO1 {
							regulator-name = "ldo1";
							regulator-min-microvolt = <0x2dc6c0>;
							regulator-max-microvolt = <0x325aa0>;
							regulator-boot-on;
							regulator-always-on;
							phandle = <0x87>;
						};

						LDO2 {
							regulator-name = "ldo2";
							regulator-min-microvolt = <0xdbba0>;
							regulator-max-microvolt = <0xdbba0>;
							regulator-boot-on;
							regulator-always-on;
							phandle = <0x88>;
						};

						LDO3 {
							regulator-name = "ldo3";
							regulator-min-microvolt = <0x1b7740>;
							regulator-max-microvolt = <0x1cfde0>;
							regulator-boot-on;
							regulator-always-on;
							phandle = <0x89>;
						};

						LDO4 {
							regulator-name = "ldo4";
							regulator-min-microvolt = <0xdbba0>;
							regulator-max-microvolt = <0xf4240>;
							regulator-boot-on;
							regulator-always-on;
							phandle = <0x8a>;
						};

						LDO5 {
							regulator-name = "ldo5";
							regulator-min-microvolt = <0x2625a0>;
							regulator-max-microvolt = <0x27ac40>;
							regulator-boot-on;
							regulator-always-on;
							phandle = <0x8b>;
						};

						LDO6 {
							regulator-name = "ldo6";
							regulator-min-microvolt = <0xdbba0>;
							regulator-max-microvolt = <0xf4240>;
							regulator-boot-on;
							regulator-always-on;
							phandle = <0x8c>;
						};

						LDO7 {
							regulator-name = "ldo7";
							regulator-min-microvolt = <0x2dc6c0>;
							regulator-max-microvolt = <0x325aa0>;
							regulator-boot-on;
							regulator-always-on;
							phandle = <0x8d>;
						};
					};
				};
			};

			i2c@30a30000 {
				compatible = "fsl,imx8mq-i2c", "fsl,imx21-i2c";
				reg = <0x30a30000 0x10000>;
				interrupts = <0x00 0x24 0x04>;
				clocks = <0x02 0xb9>;
				#address-cells = <0x01>;
				#size-cells = <0x00>;
				status = "disabled";
				phandle = <0x8e>;
			};

			i2c@30a40000 {
				compatible = "fsl,imx8mq-i2c", "fsl,imx21-i2c";
				reg = <0x30a40000 0x10000>;
				interrupts = <0x00 0x25 0x04>;
				clocks = <0x02 0xba>;
				#address-cells = <0x01>;
				#size-cells = <0x00>;
				status = "disabled";
				phandle = <0x8f>;
			};

			i2c@30a50000 {
				compatible = "fsl,imx8mq-i2c", "fsl,imx21-i2c";
				reg = <0x30a50000 0x10000>;
				interrupts = <0x00 0x26 0x04>;
				clocks = <0x02 0xbb>;
				#address-cells = <0x01>;
				#size-cells = <0x00>;
				status = "disabled";
				clock-frequency = <0x61a80>;
				pinctrl-names = "default";
				pinctrl-0 = <0x2d>;
				phandle = <0x90>;

				ft5426_ts@38 {
					compatible = "focaltech,fts";
					reg = <0x38>;
					pinctrl-0 = <0x2e>;
					interrupt-parent = <0x2f>;
					interrupts = <0x0d 0x02>;
					focaltech,reset-gpio = <0x2c 0x04 0x01>;
					focaltech,irq-gpio = <0x2f 0x0d 0x02>;
					focaltech,max-touch-number = <0x0a>;
					focaltech,panel-type = <0x54260002>;
					focaltech,display-coords = <0x00 0x00 0x2d0 0x500>;
					focaltech,have-key;
					focaltech,key-number = <0x03>;
					focaltech,keys = <0x8b 0x66 0x9e>;
					focaltech,key-y-coord = <0x7d0>;
					focaltech,key-x-coords = <0xc8 0x258 0x320>;
					status = "disabled";
					phandle = <0x91>;
				};

				gt911_ts@14 {
					compatible = "goodix,gt911";
					reg = <0x14>;
					pinctrl-names = "default";
					pinctrl-0 = <0x2e>;
					interrupt-parent = <0x2f>;
					interrupts = <0x0d 0x02>;
					irq-gpios = <0x2f 0x0d 0x00>;
					reset-gpios = <0x2c 0x04 0x00>;
					touchscreen-size-x = <0x2d0>;
					touchscreen-size-y = <0x500>;
					status = "disabled";
					phandle = <0x92>;
				};
			};

			serial@30a60000 {
				compatible = "fsl,imx8mq-uart", "fsl,imx6q-uart";
				reg = <0x30a60000 0x10000>;
				interrupts = <0x00 0x1d 0x04>;
				clocks = <0x02 0xcd 0x02 0xcd>;
				clock-names = "ipg", "per";
				dmas = <0x22 0x1c 0x04 0x00 0x22 0x1d 0x04 0x00>;
				dma-names = "rx", "tx";
				status = "okay";
				pinctrl-names = "default";
				pinctrl-0 = <0x30>;
				assigned-clocks = <0x02 0x97>;
				assigned-clock-parents = <0x02 0x47>;
				fsl,uart-has-rtscts;
				resets = <0x31>;
				phandle = <0x93>;
			};

			mipi_csi1@30a70000 {
				compatible = "fsl,mxc-mipi-csi2_yav";
				reg = <0x30a70000 0x1000>;
				interrupts = <0x00 0x2c 0x04>;
				clocks = <0x02 0xa7 0x02 0xa9 0x02 0xa8>;
				clock-names = "clk_core", "clk_esc", "clk_pxl";
				assigned-clocks = <0x02 0xa7 0x02 0xa8 0x02 0xa9>;
				assigned-clock-rates = <0x7ed6b40 0x5f5e100 0x3ef1480>;
				power-domains = <0x32>;
				csis-phy-reset = <0x27 0x4c 0x07>;
				phy-gpr = <0x33 0x88>;
				status = "disabled";
				#address-cells = <0x01>;
				#size-cells = <0x00>;
				phandle = <0x94>;

				port {

					endpoint@1 {
						remote-endpoint = <0x34>;
						phandle = <0x35>;
					};
				};
			};

			csi1_bridge@30a90000 {
				compatible = "fsl,imx8mq-csi", "fsl,imx6s-csi";
				reg = <0x30a90000 0x10000>;
				interrupts = <0x00 0x2a 0x04>;
				clocks = <0x02 0x00 0x02 0xe0 0x02 0x00>;
				clock-names = "disp-axi", "csi_mclk", "disp_dcic";
				status = "disabled";
				fsl,mipi-mode;
				fsl,two-8bit-sensor-mode;
				phandle = <0x95>;

				port {

					endpoint {
						remote-endpoint = <0x35>;
						phandle = <0x34>;
					};
				};
			};

			mailbox@30aa0000 {
				compatible = "fsl,imx8mq-mu", "fsl,imx6sx-mu";
				reg = <0x30aa0000 0x10000>;
				interrupts = <0x00 0x58 0x04>;
				clocks = <0x02 0xfd>;
				#mbox-cells = <0x02>;
				phandle = <0x96>;
			};

			mmc@30b40000 {
				compatible = "fsl,imx8mq-usdhc", "fsl,imx7d-usdhc";
				reg = <0x30b40000 0x10000>;
				interrupts = <0x00 0x16 0x04>;
				clocks = <0x02 0xec 0x02 0x69 0x02 0xd2>;
				clock-names = "ipg", "ahb", "per";
				fsl,tuning-start-tap = <0x14>;
				fsl,tuning-step = <0x02>;
				bus-width = <0x08>;
				status = "okay";
				pinctrl-names = "default", "state_100mhz", "state_200mhz";
				pinctrl-0 = <0x36>;
				pinctrl-1 = <0x37>;
				pinctrl-2 = <0x38>;
				non-removable;
				no-sdio;
				no-1-8-v;
				phandle = <0x97>;
			};

			mmc@30b50000 {
				compatible = "fsl,imx8mq-usdhc", "fsl,imx7d-usdhc";
				reg = <0x30b50000 0x10000>;
				interrupts = <0x00 0x17 0x04>;
				clocks = <0x02 0xec 0x02 0x69 0x02 0xd3>;
				clock-names = "ipg", "ahb", "per";
				fsl,tuning-start-tap = <0x14>;
				fsl,tuning-step = <0x02>;
				bus-width = <0x04>;
				status = "okay";
				pinctrl-names = "default";
				pinctrl-0 = <0x39>;
				vmmc-supply = <0x3a>;
				mmc-pwrseq = <0x3b>;
				no-1-8-v;
				non-removable;
				pm-ignore-notify;
				keep-power-in-suspend;
				#address-cells = <0x01>;
				#size-cells = <0x00>;
				phandle = <0x98>;

				bcrmf@1 {
					reg = <0x01>;
					compatible = "brcm,bcm4329-fmac";
					interrupt-parent = <0x3c>;
					interrupts = <0x0c 0x08>;
					interrupt-names = "host-wake";
					phandle = <0x99>;
				};
			};

			mipi_csi2@30b60000 {
				compatible = "fsl,mxc-mipi-csi2_yav";
				reg = <0x30b60000 0x1000>;
				interrupts = <0x00 0x2d 0x04>;
				clocks = <0x02 0xaa 0x02 0xac 0x02 0xab>;
				clock-names = "clk_core", "clk_esc", "clk_pxl";
				assigned-clocks = <0x02 0xaa 0x02 0xab 0x02 0xac>;
				assigned-clock-rates = <0x7ed6b40 0x5f5e100 0x3ef1480>;
				power-domains = <0x3d>;
				csis-phy-reset = <0x27 0x50 0x07>;
				phy-gpr = <0x33 0xa4>;
				status = "disabled";
				phandle = <0x9a>;
			};

			csi2_bridge@30b80000 {
				compatible = "fsl,imx8mq-csi", "fsl,imx6s-csi";
				reg = <0x30b80000 0x10000>;
				interrupts = <0x00 0x2b 0x04>;
				clocks = <0x02 0x00 0x02 0xe1 0x02 0x00>;
				clock-names = "disp-axi", "csi_mclk", "disp_dcic";
				status = "disabled";
				phandle = <0x9b>;
			};

			spi@30bb0000 {
				#address-cells = <0x01>;
				#size-cells = <0x00>;
				compatible = "fsl,imx8mq-qspi", "fsl,imx7d-qspi";
				reg = <0x30bb0000 0x10000 0x8000000 0x10000000>;
				reg-names = "QuadSPI", "QuadSPI-memory";
				interrupts = <0x00 0x6b 0x04>;
				clocks = <0x02 0xc3 0x02 0xc3>;
				clock-names = "qspi_en", "qspi";
				status = "disabled";
				phandle = <0x9c>;
			};

			dma-controller@30bd0000 {
				compatible = "fsl,imx8mq-sdma", "fsl,imx7d-sdma";
				reg = <0x30bd0000 0x10000>;
				interrupts = <0x00 0x02 0x04>;
				clocks = <0x02 0xe3 0x02 0x74>;
				clock-names = "ipg", "ahb";
				#dma-cells = <0x03>;
				fsl,sdma-ram-script-name = "imx/sdma/sdma-imx7d.bin";
				phandle = <0x22>;
			};

			ethernet@30be0000 {
				compatible = "fsl,imx8mq-fec", "fsl,imx6sx-fec";
				reg = <0x30be0000 0x10000>;
				interrupts = <0x00 0x76 0x04 0x00 0x77 0x04 0x00 0x78 0x04 0x00 0x79 0x04>;
				clocks = <0x02 0xb6 0x02 0xb6 0x02 0x8a 0x02 0x89 0x02 0x8b>;
				clock-names = "ipg", "ahb", "ptp", "enet_clk_ref", "enet_out";
				assigned-clocks = <0x02 0x68 0x02 0x8a 0x02 0x89 0x02 0x8b>;
				assigned-clock-parents = <0x02 0x4c 0x02 0x50 0x02 0x51 0x02 0x4f>;
				assigned-clock-rates = <0x00 0x5f5e100 0x7735940 0x00>;
				fsl,num-tx-queues = <0x03>;
				fsl,num-rx-queues = <0x03>;
				nvmem-cells = <0x3e>;
				nvmem-cell-names = "mac-address";
				fsl,stop-mode = <0x33 0x10 0x03>;
				status = "okay";
				pinctrl-names = "default";
				pinctrl-0 = <0x3f>;
				phy-mode = "rgmii-id";
				phy-handle = <0x40>;
				fsl,magic-packet;
				phy-reset-gpios = <0x2c 0x09 0x01>;
				phandle = <0x9d>;

				mdio {
					#address-cells = <0x01>;
					#size-cells = <0x00>;

					ethernet-phy@0 {
						compatible = "ethernet-phy-ieee802.3-c22";
						reg = <0x04>;
						at803x,eee-disabled;
						phandle = <0x40>;
					};
				};
			};
		};

		bus@32c00000 {
			compatible = "fsl,aips-bus", "simple-bus";
			reg = <0x32c00000 0x400000>;
			#address-cells = <0x01>;
			#size-cells = <0x01>;
			ranges = <0x32c00000 0x32c00000 0x400000>;
			phandle = <0x9e>;

			hdmi@32c00000 {
				reg = <0x32c00000 0x100000 0x32e40000 0x40000>;
				interrupts = <0x00 0x10 0x04 0x00 0x19 0x04>;
				interrupt-names = "plug_in", "plug_out";
				compatible = "cdn,imx8mq-hdmi";
				lane-mapping = <0xe4>;
				status = "disabled";
				phandle = <0x9f>;
			};

			interrupt-controller@32e2d000 {
				compatible = "fsl,imx8m-irqsteer", "fsl,imx-irqsteer";
				reg = <0x32e2d000 0x1000>;
				interrupts = <0x00 0x12 0x04>;
				clocks = <0x02 0xf8>;
				clock-names = "ipg";
				fsl,channel = <0x00>;
				fsl,num-irqs = <0x40>;
				interrupt-controller;
				#interrupt-cells = <0x01>;
				status = "okay";
				phandle = <0x41>;
			};

			display-controller@32e00000 {
				#address-cells = <0x01>;
				#size-cells = <0x00>;
				compatible = "nxp,imx8mq-dcss";
				reg = <0x32e00000 0x2d000 0x32e2f000 0x1000>;
				interrupts = <0x06 0x08 0x09 0x10 0x11>;
				interrupt-names = "ctxld", "ctxld_kick", "vblank", "dtrc_ch1", "dtrc_ch2";
				interrupt-parent = <0x41>;
				clocks = <0x02 0xf8 0x02 0xf7 0x02 0xf9 0x02 0xfe 0x02 0x7a 0x02 0x10a 0x42>;
				clock-names = "apb", "axi", "rtrm", "pix", "dtrc", "pll_src", "pll_phy_ref";
				assigned-clocks = <0x02 0x6b 0x02 0x6d 0x02 0x10a>;
				assigned-clock-parents = <0x02 0x4e 0x02 0x4e 0x02 0x03>;
				assigned-clock-rates = <0x2faf0800 0x17d78400>;
				status = "disabled";
				phandle = <0xa0>;
			};
		};

		usb@38100000 {
			compatible = "fsl,imx8mq-dwc3", "snps,dwc3";
			reg = <0x38100000 0x10000>;
			clocks = <0x02 0xce 0x02 0x98 0x02 0x01>;
			clock-names = "bus_early", "ref", "suspend";
			assigned-clocks = <0x02 0x6e 0x02 0x98>;
			assigned-clock-parents = <0x02 0x56 0x02 0x48>;
			assigned-clock-rates = <0x1dcd6500 0x5f5e100>;
			interrupts = <0x00 0x28 0x04>;
			phys = <0x43 0x43>;
			phy-names = "usb2-phy", "usb3-phy";
			power-domains = <0x44>;
			snps,parkmode-disable-ss-quirk;
			snps,dis_rxdet_inp3_quirk;
			status = "okay";
			dr_mode = "host";
			phandle = <0xa1>;
		};

		usb-phy@381f0040 {
			compatible = "fsl,imx8mq-usb-phy";
			reg = <0x381f0040 0x40>;
			clocks = <0x02 0xd0>;
			clock-names = "phy";
			assigned-clocks = <0x02 0x99>;
			assigned-clock-parents = <0x02 0x48>;
			assigned-clock-rates = <0x5f5e100>;
			#phy-cells = <0x00>;
			status = "okay";
			phandle = <0x43>;
		};

		usb@38200000 {
			compatible = "fsl,imx8mq-dwc3", "snps,dwc3";
			reg = <0x38200000 0x10000>;
			clocks = <0x02 0xcf 0x02 0x98 0x02 0x01>;
			clock-names = "bus_early", "ref", "suspend";
			assigned-clocks = <0x02 0x6e 0x02 0x98>;
			assigned-clock-parents = <0x02 0x56 0x02 0x48>;
			assigned-clock-rates = <0x1dcd6500 0x5f5e100>;
			interrupts = <0x00 0x29 0x04>;
			phys = <0x45 0x45>;
			phy-names = "usb2-phy", "usb3-phy";
			power-domains = <0x46>;
			snps,parkmode-disable-ss-quirk;
			snps,dis_rxdet_inp3_quirk;
			status = "okay";
			dr_mode = "host";
			phandle = <0xa2>;
		};

		usb-phy@382f0040 {
			compatible = "fsl,imx8mq-usb-phy";
			reg = <0x382f0040 0x40>;
			clocks = <0x02 0xd1>;
			clock-names = "phy";
			assigned-clocks = <0x02 0x99>;
			assigned-clock-parents = <0x02 0x48>;
			assigned-clock-rates = <0x5f5e100>;
			#phy-cells = <0x00>;
			status = "okay";
			phandle = <0x45>;
		};

		dma-apbh@33000000 {
			compatible = "fsl,imx7d-dma-apbh", "fsl,imx28-dma-apbh";
			reg = <0x33000000 0x2000>;
			interrupts = <0x00 0x0c 0x04 0x00 0x0c 0x04 0x00 0x0c 0x04 0x00 0x0c 0x04>;
			interrupt-names = "gpmi0", "gpmi1", "gpmi2", "gpmi3";
			#dma-cells = <0x01>;
			dma-channels = <0x04>;
			clocks = <0x02 0x100>;
			phandle = <0x47>;
		};

		gpmi-nand@33002000 {
			compatible = "fsl,imx7d-gpmi-nand";
			#address-cells = <0x01>;
			#size-cells = <0x01>;
			reg = <0x33002000 0x2000 0x33004000 0x4000>;
			reg-names = "gpmi-nand", "bch";
			interrupts = <0x00 0x0e 0x04>;
			interrupt-names = "bch";
			clocks = <0x02 0xe2 0x02 0x100>;
			clock-names = "gpmi_io", "gpmi_bch_apb";
			dmas = <0x47 0x00>;
			dma-names = "rx-tx";
			status = "disabled";
			phandle = <0xa3>;
		};

		pcie@33800000 {
			compatible = "fsl,imx8mq-pcie";
			reg = <0x33800000 0x400000 0x1ff00000 0x80000>;
			reg-names = "dbi", "config";
			#address-cells = <0x03>;
			#size-cells = <0x02>;
			device_type = "pci";
			bus-range = <0x00 0xff>;
			ranges = <0x81000000 0x00 0x00 0x1ff80000 0x00 0x10000 0x82000000 0x00 0x18000000 0x18000000 0x00 0x7f00000>;
			num-lanes = <0x01>;
			interrupts = <0x00 0x7a 0x04>;
			interrupt-names = "msi";
			#interrupt-cells = <0x01>;
			interrupt-map-mask = <0x00 0x00 0x00 0x07>;
			interrupt-map = <0x00 0x00 0x00 0x01 0x08 0x00 0x7d 0x04 0x00 0x00 0x00 0x02 0x08 0x00 0x7c 0x04 0x00 0x00 0x00 0x03 0x08 0x00 0x7b 0x04 0x00 0x00 0x00 0x04 0x08 0x00 0x7a 0x04>;
			fsl,max-link-speed = <0x02>;
			linux,pci-domain = <0x00>;
			power-domains = <0x48>;
			resets = <0x27 0x1a 0x27 0x1c 0x27 0x1d>;
			reset-names = "pciephy", "apps", "turnoff";
			assigned-clocks = <0x02 0x7c 0x02 0x7d 0x02 0x7e>;
			assigned-clock-parents = <0x02 0x54 0x02 0x50 0x02 0x47>;
			assigned-clock-rates = <0xee6b280 0x5f5e100 0x989680>;
			status = "disabled";
			phandle = <0xa4>;
		};

		pcie@33c00000 {
			compatible = "fsl,imx8mq-pcie";
			reg = <0x33c00000 0x400000 0x27f00000 0x80000>;
			reg-names = "dbi", "config";
			#address-cells = <0x03>;
			#size-cells = <0x02>;
			device_type = "pci";
			ranges = <0x81000000 0x00 0x00 0x27f80000 0x00 0x10000 0x82000000 0x00 0x20000000 0x20000000 0x00 0x7f00000>;
			num-lanes = <0x01>;
			interrupts = <0x00 0x4a 0x04>;
			interrupt-names = "msi";
			#interrupt-cells = <0x01>;
			interrupt-map-mask = <0x00 0x00 0x00 0x07>;
			interrupt-map = <0x00 0x00 0x00 0x01 0x08 0x00 0x4d 0x04 0x00 0x00 0x00 0x02 0x08 0x00 0x4c 0x04 0x00 0x00 0x00 0x03 0x08 0x00 0x4b 0x04 0x00 0x00 0x00 0x04 0x08 0x00 0x4a 0x04>;
			fsl,max-link-speed = <0x02>;
			linux,pci-domain = <0x01>;
			power-domains = <0x48>;
			resets = <0x27 0x22 0x27 0x24 0x27 0x25>;
			reset-names = "pciephy", "apps", "turnoff";
			assigned-clocks = <0x02 0xad 0x02 0xae 0x02 0xaf>;
			assigned-clock-parents = <0x02 0x54 0x02 0x50 0x02 0x47>;
			assigned-clock-rates = <0xee6b280 0x5f5e100 0x989680>;
			status = "disabled";
			phandle = <0xa5>;
		};

		pcie_ep@33c00000 {
			compatible = "fsl,imx8mq-pcie-ep";
			reg = <0x33c00000 0x400000 0x20000000 0x8000000>;
			reg-names = "regs", "addr_space";
			num-lanes = <0x01>;
			interrupts = <0x00 0x50 0x04>;
			interrupt-names = "dma";
			fsl,max-link-speed = <0x02>;
			power-domains = <0x48>;
			resets = <0x27 0x22 0x27 0x24 0x27 0x25>;
			reset-names = "pciephy", "apps", "turnoff";
			num-ib-windows = <0x04>;
			num-ob-windows = <0x04>;
			status = "disabled";
			phandle = <0xa6>;
		};

		interrupt-controller@38800000 {
			compatible = "arm,gic-v3";
			reg = <0x38800000 0x10000 0x38880000 0xc0000 0x31000000 0x2000 0x31010000 0x2000 0x31020000 0x2000>;
			#interrupt-cells = <0x03>;
			interrupt-controller;
			interrupts = <0x01 0x09 0x04>;
			interrupt-parent = <0x08>;
			phandle = <0x08>;
		};

		ddr-pmu@3d800000 {
			compatible = "fsl,imx8mq-ddr-pmu", "fsl,imx8m-ddr-pmu";
			reg = <0x3d800000 0x400000>;
			interrupt-parent = <0x08>;
			interrupts = <0x00 0x62 0x04>;
		};

		vpu@38300000 {
			compatible = "nxp,imx8mq-hantro";
			reg = <0x38300000 0x200000>;
			reg-names = "regs_hantro";
			interrupts = <0x00 0x07 0x04 0x00 0x08 0x04>;
			interrupt-names = "irq_hantro_g1", "irq_hantro_g2";
			clocks = <0x02 0xe5 0x02 0xe6 0x02 0xdf>;
			clock-names = "clk_hantro_g1", "clk_hantro_g2", "clk_hantro_bus";
			assigned-clocks = <0x02 0x78 0x02 0x79 0x02 0x6a>;
			assigned-clock-parents = <0x02 0x16 0x02 0x16 0x02 0x4e>;
			assigned-clock-rates = <0x23c34600 0x23c34600 0x2faf0800>;
			power-domains = <0x49>;
			status = "okay";
			phandle = <0xa7>;
		};

		vpu_v4l2 {
			compatible = "nxp,imx8m-vsiv4l2";
			status = "disabled";
			phandle = <0xa8>;
		};
	};

	gpu3d@38000000 {
		compatible = "fsl,imx8mq-gpu", "fsl,imx6q-gpu";
		reg = <0x00 0x38000000 0x00 0x40000 0x00 0x40000000 0x00 0xc0000000 0x00 0x00 0x00 0x10000000>;
		reg-names = "iobase_3d", "phys_baseaddr", "contiguous_mem";
		interrupts = <0x00 0x03 0x04>;
		interrupt-names = "irq_3d";
		clocks = <0x02 0xd7 0x02 0x66 0x02 0x6f 0x02 0x70>;
		clock-names = "gpu3d_clk", "gpu3d_shader_clk", "gpu3d_axi_clk", "gpu3d_ahb_clk";
		assigned-clocks = <0x02 0x61 0x02 0x64 0x02 0x6f 0x02 0x70>;
		assigned-clock-parents = <0x02 0x11 0x02 0x11 0x02 0x11 0x02 0x11>;
		assigned-clock-rates = <0x2faf0800 0x2faf0800 0x2faf0800 0x2faf0800>;
		power-domains = <0x4a>;
		status = "okay";
		phandle = <0xa9>;
	};

	chosen {
		stdout-path = "/soc@0/bus@30800000/serial@30860000";
	};

	memory@40000000 {
		device_type = "memory";
		reg = <0x00 0x40000000 0x00 0x40000000>;
	};

	reserved-memory {
		#address-cells = <0x02>;
		#size-cells = <0x02>;
		ranges;
		phandle = <0xaa>;

		linux,cma {
			compatible = "shared-dma-pool";
			reusable;
			size = <0x00 0x3c000000>;
			alloc-ranges = <0x00 0x40000000 0x00 0x40000000>;
			linux,cma-default;
		};
	};

	clock-pmic {
		compatible = "fixed-clock";
		#clock-cells = <0x00>;
		clock-frequency = <0x8000>;
		clock-output-names = "pmic_osc";
		phandle = <0x2b>;
	};

	leds {
		compatible = "gpio-leds";
		pinctrl-names = "default";
		pinctrl-0 = <0x4b>;
		status = "okay";

		sys_led {
			label = "sys_led";
			gpios = <0x2c 0x05 0x00>;
			default-state = "on";
			linux,default-trigger = "heartbeat";
		};

		usr_led {
			label = "usr_led";
			gpios = <0x2c 0x08 0x00>;
			default-state = "on";
		};
	};

	gpio_keys {
		compatible = "gpio-keys";
		pinctrl-names = "default";
		pinctrl-0 = <0x4c>;

		home {
			label = "home Button";
			gpios = <0x2f 0x07 0x01>;
			linux,code = <0x66>;
			gpio-key,wakeup;
		};

		back {
			label = "back Button";
			gpios = <0x2f 0x06 0x01>;
			linux,code = <0x19c>;
		};
	};

	regulators {
		compatible = "simple-bus";
		#address-cells = <0x01>;
		#size-cells = <0x00>;

		regulator-usb1-vcc {
			compatible = "regulator-fixed";
			pinctrl-names = "default";
			pinctrl-0 = <0x4d>;
			regulator-name = "usb1_pwr_en";
			regulator-min-microvolt = <0x325aa0>;
			regulator-max-microvolt = <0x325aa0>;
			enable-active-high;
			regulator-always-on;
			regulator-boot-on;
			startup-delay-us = <0x27100>;
			gpio = <0x2c 0x0c 0x01>;
			phandle = <0xab>;
		};

		regulator@1 {
			compatible = "regulator-fixed";
			reg = <0x01>;
			pinctrl-names = "default";
			pinctrl-0 = <0x4e>;
			regulator-name = "WF_3V3";
			regulator-min-microvolt = <0x325aa0>;
			regulator-max-microvolt = <0x325aa0>;
			gpio = <0x3c 0x14 0x00>;
			regulator-always-on;
			enable-active-high;
			phandle = <0x3a>;
		};
	};

	sdio-pwrseq {
		compatible = "mmc-pwrseq-simple";
		pinctrl-names = "default";
		pinctrl-0 = <0x4f>;
		reset-gpios = <0x3c 0x13 0x01>;
		phandle = <0x3b>;
	};

	bt_reset {
		compatible = "gpio-reset";
		reset-gpios = <0x50 0x0b 0x01>;
		reset-delay-us = <0x3e8>;
		reset-post-delay-ms = <0x28>;
		#reset-cells = <0x00>;
		phandle = <0x31>;
	};

	sound-hdmi {
		compatible = "fsl,imx-audio-hdmi";
		model = "imx-audio-hdmi";
		audio-cpu = <0x51>;
		protocol = <0x01>;
		hdmi-out;
		constraint-rate = <0xac44 0x15888 0x2b110 0x7d00 0xbb80 0x17700 0x2ee00>;
		status = "disabled";
		phandle = <0xac>;
	};

	pwm-backlight {
		compatible = "pwm-backlight";
		pwms = <0x52 0x00 0x9c40 0x00>;
		brightness-levels = <0x00 0x08 0x20 0x40 0x60 0x80 0xa0 0xc0 0xe0 0xff>;
		default-brightness-level = <0x08>;
		enable-pwm-on;
		status = "disabled";
		phandle = <0xad>;
	};

	__symbols__ {
		ckil = "/clock-ckil";
		osc_25m = "/clock-osc-25m";
		osc_27m = "/clock-osc-27m";
		hdmi_phy_27m = "/clock-hdmi-phy-27m";
		clk_ext1 = "/clock-ext1";
		clk_ext2 = "/clock-ext2";
		clk_ext3 = "/clock-ext3";
		clk_ext4 = "/clock-ext4";
		A53_0 = "/cpus/cpu@0";
		A53_1 = "/cpus/cpu@1";
		A53_2 = "/cpus/cpu@2";
		A53_3 = "/cpus/cpu@3";
		A53_L2 = "/cpus/l2-cache0";
		CPU_SLEEP = "/cpus/idle-states/cpu-sleep";
		a53_opp_table = "/opp-table";
		cpu_thermal = "/thermal-zones/cpu-thermal";
		cpu_alert = "/thermal-zones/cpu-thermal/trips/cpu-alert";
		cpu_alert0 = "/thermal-zones/cpu-thermal/trips/trip0";
		cpu_alert1 = "/thermal-zones/cpu-thermal/trips/trip1";
		soc = "/soc@0";
		caam_sm = "/soc@0/caam-sm@100000";
		aips1 = "/soc@0/bus@30000000";
		sai1 = "/soc@0/bus@30000000/sai@30010000";
		sai6 = "/soc@0/bus@30000000/sai@30030000";
		sai5 = "/soc@0/bus@30000000/sai@30040000";
		sai4 = "/soc@0/bus@30000000/sai@30050000";
		gpio1 = "/soc@0/bus@30000000/gpio@30200000";
		gpio2 = "/soc@0/bus@30000000/gpio@30210000";
		gpio3 = "/soc@0/bus@30000000/gpio@30220000";
		gpio4 = "/soc@0/bus@30000000/gpio@30230000";
		gpio5 = "/soc@0/bus@30000000/gpio@30240000";
		tmu = "/soc@0/bus@30000000/tmu@30260000";
		throttle_devfreq = "/soc@0/bus@30000000/tmu@30260000/throttle-cfgs/devfreq";
		wdog1 = "/soc@0/bus@30000000/watchdog@30280000";
		wdog2 = "/soc@0/bus@30000000/watchdog@30290000";
		wdog3 = "/soc@0/bus@30000000/watchdog@302a0000";
		sdma2 = "/soc@0/bus@30000000/dma-controller@302c0000";
		lcdif = "/soc@0/bus@30000000/lcd-controller@30320000";
		lcdif_mipi_dsi = "/soc@0/bus@30000000/lcd-controller@30320000/port/endpoint";
		iomuxc = "/soc@0/bus@30000000/pinctrl@30330000";
		pinctrl_ir_recv = "/soc@0/bus@30000000/pinctrl@30330000/ir-recv";
		pinctrl_pmic = "/soc@0/bus@30000000/pinctrl@30330000/pmicirq";
		pinctrl_fec1 = "/soc@0/bus@30000000/pinctrl@30330000/fec1grp";
		pinctrl_i2c1 = "/soc@0/bus@30000000/pinctrl@30330000/i2c1grp";
		pinctrl_uart1 = "/soc@0/bus@30000000/pinctrl@30330000/uart1grp";
		pinctrl_usdhc1 = "/soc@0/bus@30000000/pinctrl@30330000/usdhc1grp";
		pinctrl_usdhc1_100mhz = "/soc@0/bus@30000000/pinctrl@30330000/usdhc1-100grp";
		pinctrl_usdhc1_200mhz = "/soc@0/bus@30000000/pinctrl@30330000/usdhc1-200grp";
		pinctrl_gpio_leds = "/soc@0/bus@30000000/pinctrl@30330000/gpio_ledsgrp";
		pinctrl_gpio_keys = "/soc@0/bus@30000000/pinctrl@30330000/gpio_keysgrp";
		pinctrl_usb1_pwr_en = "/soc@0/bus@30000000/pinctrl@30330000/usb1_pwr_en";
		pinctrl_usdhc2 = "/soc@0/bus@30000000/pinctrl@30330000/usdhc2grp";
		pinctrl_wlan = "/soc@0/bus@30000000/pinctrl@30330000/wlangrp";
		pinctrl_reg3V3wf = "/soc@0/bus@30000000/pinctrl@30330000/reg3V3wfgrp";
		pinctrl_uart4 = "/soc@0/bus@30000000/pinctrl@30330000/uart4grp";
		pinctrl_pwm1 = "/soc@0/bus@30000000/pinctrl@30330000/pwm1_grp";
		pinctrl_ts = "/soc@0/bus@30000000/pinctrl@30330000/ts_pinsgrp";
		pinctrl_i2c4 = "/soc@0/bus@30000000/pinctrl@30330000/i2c4grp";
		pinctrl_csi1 = "/soc@0/bus@30000000/pinctrl@30330000/csi1grp";
		pinctrl_wdog = "/soc@0/bus@30000000/pinctrl@30330000/wdog1grp";
		iomuxc_gpr = "/soc@0/bus@30000000/syscon@30340000";
		mux = "/soc@0/bus@30000000/syscon@30340000/mux-controller";
		ocotp = "/soc@0/bus@30000000/efuse@30350000";
		imx8mq_uid = "/soc@0/bus@30000000/efuse@30350000/soc-uid@4";
		cpu_speed_grade = "/soc@0/bus@30000000/efuse@30350000/speed-grade@10";
		fec_mac_address = "/soc@0/bus@30000000/efuse@30350000/mac-address@90";
		imx8mq_soc = "/soc@0/bus@30000000/efuse@30350000/imx8mq-soc";
		anatop = "/soc@0/bus@30000000/syscon@30360000";
		irq_sec_vio = "/soc@0/bus@30000000/caam_secvio";
		caam_snvs = "/soc@0/bus@30000000/caam-snvs@30370000";
		snvs = "/soc@0/bus@30000000/snvs@30370000";
		snvs_rtc = "/soc@0/bus@30000000/snvs@30370000/snvs-rtc-lp";
		snvs_pwrkey = "/soc@0/bus@30000000/snvs@30370000/snvs-powerkey";
		clk = "/soc@0/bus@30000000/clock-controller@30380000";
		src = "/soc@0/bus@30000000/reset-controller@30390000";
		gpc = "/soc@0/bus@30000000/gpc@303a0000";
		pgc_mipi = "/soc@0/bus@30000000/gpc@303a0000/pgc/power-domain@0";
		pgc_pcie = "/soc@0/bus@30000000/gpc@303a0000/pgc/power-domain@1";
		pgc_otg1 = "/soc@0/bus@30000000/gpc@303a0000/pgc/power-domain@2";
		pgc_otg2 = "/soc@0/bus@30000000/gpc@303a0000/pgc/power-domain@3";
		pgc_ddr1 = "/soc@0/bus@30000000/gpc@303a0000/pgc/power-domain@4";
		pgc_gpu = "/soc@0/bus@30000000/gpc@303a0000/pgc/power-domain@5";
		pgc_vpu = "/soc@0/bus@30000000/gpc@303a0000/pgc/power-domain@6";
		pgc_disp = "/soc@0/bus@30000000/gpc@303a0000/pgc/power-domain@7";
		pgc_mipi_csi1 = "/soc@0/bus@30000000/gpc@303a0000/pgc/power-domain@8";
		pgc_mipi_csi2 = "/soc@0/bus@30000000/gpc@303a0000/pgc/power-domain@9";
		pgc_pcie2 = "/soc@0/bus@30000000/gpc@303a0000/pgc/power-domain@a";
		aips2 = "/soc@0/bus@30400000";
		pwm1 = "/soc@0/bus@30400000/pwm@30660000";
		pwm2 = "/soc@0/bus@30400000/pwm@30670000";
		pwm3 = "/soc@0/bus@30400000/pwm@30680000";
		pwm4 = "/soc@0/bus@30400000/pwm@30690000";
		system_counter = "/soc@0/bus@30400000/timer@306a0000";
		aips3 = "/soc@0/bus@30800000";
		spdif1 = "/soc@0/bus@30800000/spdif@30810000";
		ecspi1 = "/soc@0/bus@30800000/spi@30820000";
		ecspi2 = "/soc@0/bus@30800000/spi@30830000";
		ecspi3 = "/soc@0/bus@30800000/spi@30840000";
		uart1 = "/soc@0/bus@30800000/serial@30860000";
		uart3 = "/soc@0/bus@30800000/serial@30880000";
		uart2 = "/soc@0/bus@30800000/serial@30890000";
		spdif2 = "/soc@0/bus@30800000/spdif@308a0000";
		sai2 = "/soc@0/bus@30800000/sai@308b0000";
		sai3 = "/soc@0/bus@30800000/sai@308c0000";
		crypto = "/soc@0/bus@30800000/crypto@30900000";
		sec_jr0 = "/soc@0/bus@30800000/crypto@30900000/jr@1000";
		sec_jr1 = "/soc@0/bus@30800000/crypto@30900000/jr@2000";
		sec_jr2 = "/soc@0/bus@30800000/crypto@30900000/jr@3000";
		mipi_dsi = "/soc@0/bus@30800000/mipi-dsi@30a00000";
		mipi_dsi_lcdif_in = "/soc@0/bus@30800000/mipi-dsi@30a00000/ports/port@0/endpoint@0";
		dphy = "/soc@0/bus@30800000/dphy@30a00300";
		i2c1 = "/soc@0/bus@30800000/i2c@30a20000";
		pmic = "/soc@0/bus@30800000/i2c@30a20000/pmic@4b";
		buck1_reg = "/soc@0/bus@30800000/i2c@30a20000/pmic@4b/regulators/BUCK1";
		buck2_reg = "/soc@0/bus@30800000/i2c@30a20000/pmic@4b/regulators/BUCK2";
		buck3_reg = "/soc@0/bus@30800000/i2c@30a20000/pmic@4b/regulators/BUCK3";
		buck4_reg = "/soc@0/bus@30800000/i2c@30a20000/pmic@4b/regulators/BUCK4";
		buck5_reg = "/soc@0/bus@30800000/i2c@30a20000/pmic@4b/regulators/BUCK5";
		buck6_reg = "/soc@0/bus@30800000/i2c@30a20000/pmic@4b/regulators/BUCK6";
		buck7_reg = "/soc@0/bus@30800000/i2c@30a20000/pmic@4b/regulators/BUCK7";
		buck8_reg = "/soc@0/bus@30800000/i2c@30a20000/pmic@4b/regulators/BUCK8";
		ldo1_reg = "/soc@0/bus@30800000/i2c@30a20000/pmic@4b/regulators/LDO1";
		ldo2_reg = "/soc@0/bus@30800000/i2c@30a20000/pmic@4b/regulators/LDO2";
		ldo3_reg = "/soc@0/bus@30800000/i2c@30a20000/pmic@4b/regulators/LDO3";
		ldo4_reg = "/soc@0/bus@30800000/i2c@30a20000/pmic@4b/regulators/LDO4";
		ldo5_reg = "/soc@0/bus@30800000/i2c@30a20000/pmic@4b/regulators/LDO5";
		ldo6_reg = "/soc@0/bus@30800000/i2c@30a20000/pmic@4b/regulators/LDO6";
		ldo7_reg = "/soc@0/bus@30800000/i2c@30a20000/pmic@4b/regulators/LDO7";
		i2c2 = "/soc@0/bus@30800000/i2c@30a30000";
		i2c3 = "/soc@0/bus@30800000/i2c@30a40000";
		i2c4 = "/soc@0/bus@30800000/i2c@30a50000";
		ft5426 = "/soc@0/bus@30800000/i2c@30a50000/ft5426_ts@38";
		gt911 = "/soc@0/bus@30800000/i2c@30a50000/gt911_ts@14";
		uart4 = "/soc@0/bus@30800000/serial@30a60000";
		mipi_csi_1 = "/soc@0/bus@30800000/mipi_csi1@30a70000";
		csi1_mipi_ep = "/soc@0/bus@30800000/mipi_csi1@30a70000/port/endpoint@1";
		csi1_bridge = "/soc@0/bus@30800000/csi1_bridge@30a90000";
		csi1_ep = "/soc@0/bus@30800000/csi1_bridge@30a90000/port/endpoint";
		mu = "/soc@0/bus@30800000/mailbox@30aa0000";
		usdhc1 = "/soc@0/bus@30800000/mmc@30b40000";
		usdhc2 = "/soc@0/bus@30800000/mmc@30b50000";
		brcmf = "/soc@0/bus@30800000/mmc@30b50000/bcrmf@1";
		mipi_csi_2 = "/soc@0/bus@30800000/mipi_csi2@30b60000";
		csi2_bridge = "/soc@0/bus@30800000/csi2_bridge@30b80000";
		qspi0 = "/soc@0/bus@30800000/spi@30bb0000";
		sdma1 = "/soc@0/bus@30800000/dma-controller@30bd0000";
		fec1 = "/soc@0/bus@30800000/ethernet@30be0000";
		ethphy0 = "/soc@0/bus@30800000/ethernet@30be0000/mdio/ethernet-phy@0";
		aips4 = "/soc@0/bus@32c00000";
		hdmi = "/soc@0/bus@32c00000/hdmi@32c00000";
		irqsteer = "/soc@0/bus@32c00000/interrupt-controller@32e2d000";
		dcss = "/soc@0/bus@32c00000/display-controller@32e00000";
		usb_dwc3_0 = "/soc@0/usb@38100000";
		usb3_phy0 = "/soc@0/usb-phy@381f0040";
		usb_dwc3_1 = "/soc@0/usb@38200000";
		usb3_phy1 = "/soc@0/usb-phy@382f0040";
		dma_apbh = "/soc@0/dma-apbh@33000000";
		gpmi = "/soc@0/gpmi-nand@33002000";
		pcie0 = "/soc@0/pcie@33800000";
		pcie1 = "/soc@0/pcie@33c00000";
		pcie1_ep = "/soc@0/pcie_ep@33c00000";
		gic = "/soc@0/interrupt-controller@38800000";
		vpu = "/soc@0/vpu@38300000";
		vpu_v4l2 = "/soc@0/vpu_v4l2";
		gpu3d = "/gpu3d@38000000";
		resmem = "/reserved-memory";
		pmic_osc = "/clock-pmic";
		reg_usb1_en = "/regulators/regulator-usb1-vcc";
		reg_3V3WF = "/regulators/regulator@1";
		wlan_pwrseq = "/sdio-pwrseq";
		bt_reset = "/bt_reset";
		hdmi_audio = "/sound-hdmi";
		backlight = "/pwm-backlight";
	};
};
